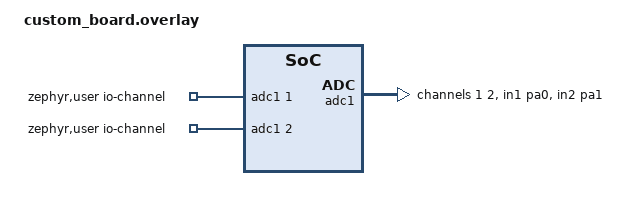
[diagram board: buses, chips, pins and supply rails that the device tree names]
/ {
    chosen {
        app-led = &green_led_2;
    };

    zephyr,user {
        io-channels = <&adc1 1>, <&adc1 2>;
    };

    aliases {
        stick-adc = &adc1;
    };
};

&adc1 {
    #address-cells = <1>;
    #size-cells = <0>;
    pinctrl-0 = <&adc1_in1_pa0 &adc1_in2_pa1>;
    pinctrl-names = "default";
    status = "okay";
    st,adc-clock-source = <SYNC>;
    st,adc-prescaler = <4>;

    channel@1 {
        reg = <1>;
        zephyr,gain = "ADC_GAIN_1";
		zephyr,reference = "ADC_REF_INTERNAL";
		zephyr,acquisition-time = <ADC_ACQ_TIME_DEFAULT>;
        zephyr,resolution = <12>;
    };

    channel@2 {
        reg = <2>;
        zephyr,gain = "ADC_GAIN_1";
		zephyr,reference = "ADC_REF_INTERNAL";
		zephyr,acquisition-time = <ADC_ACQ_TIME_DEFAULT>;
        zephyr,resolution = <12>;
    };
};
